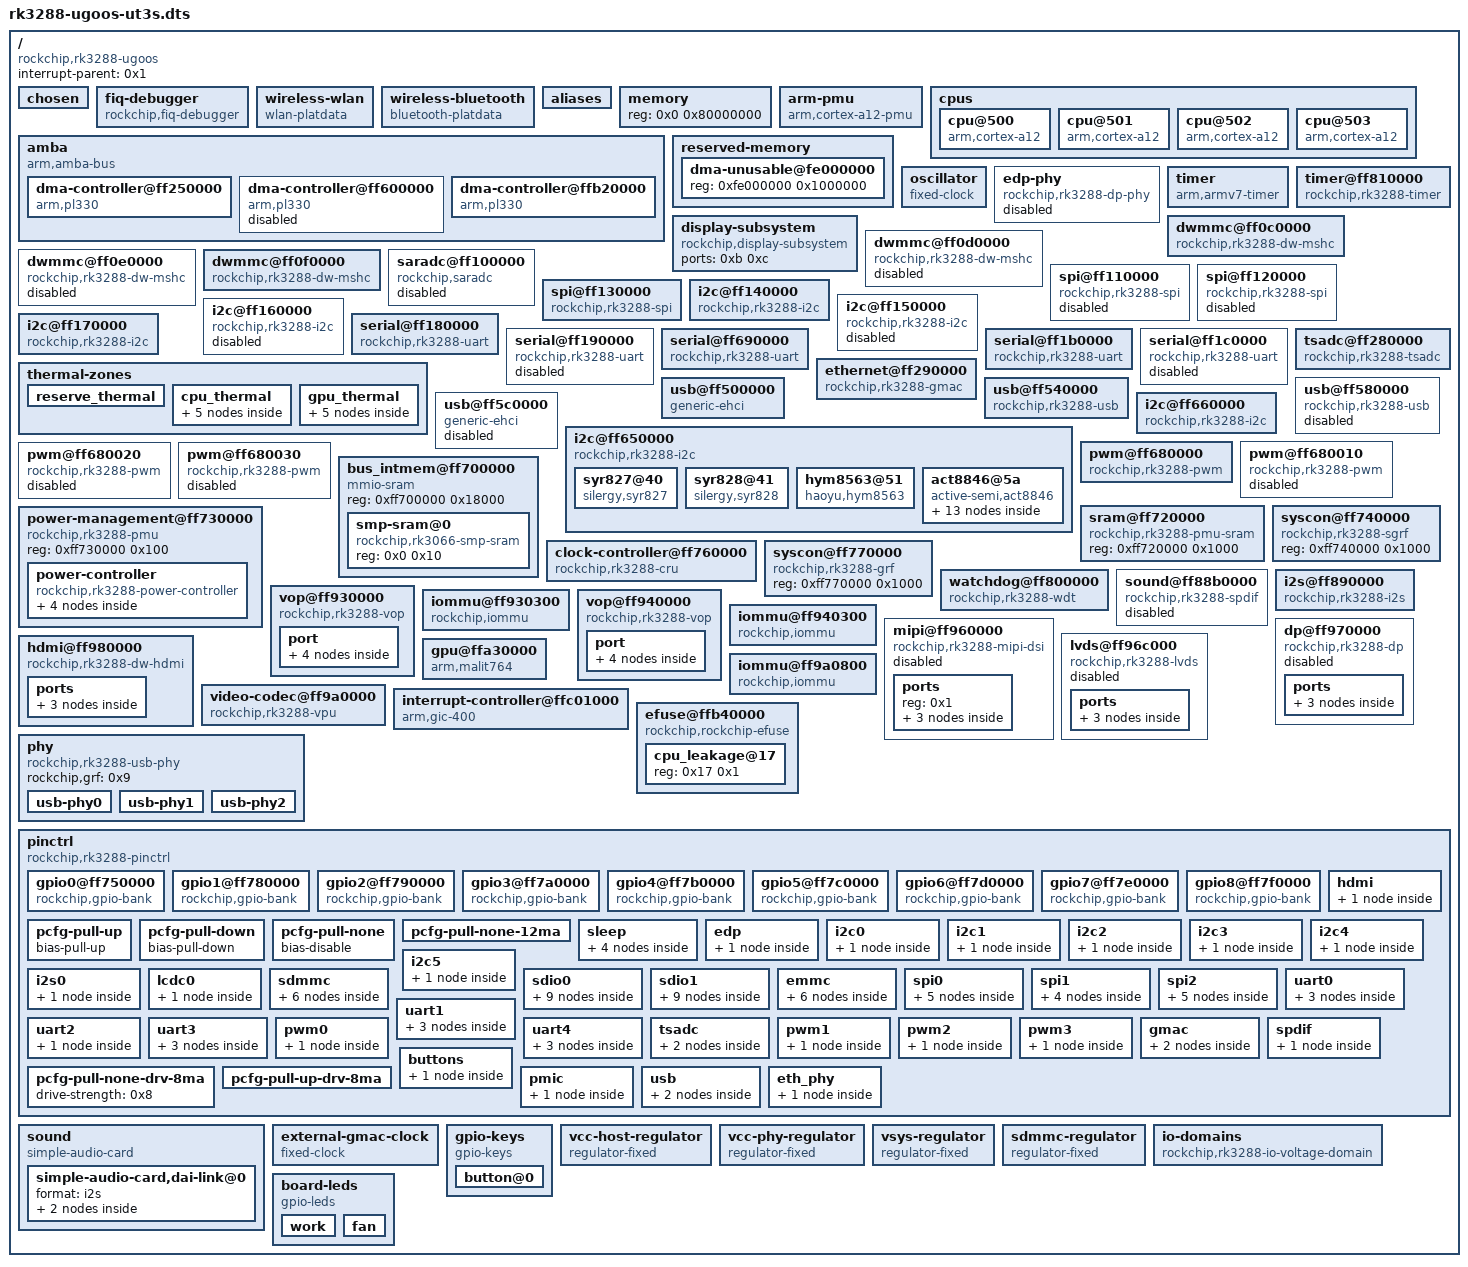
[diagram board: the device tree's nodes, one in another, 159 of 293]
/dts-v1/;

/ {
	#address-cells = <0x1>;
	#size-cells = <0x1>;
	compatible = "rockchip,rk3288-ugoos", "rockchip,rk3288";
	interrupt-parent = <0x1>;

	// Omegamoon >> Beware, 'bootargs' overrules hardcoded defconfig settings, and extends bootloader cmdline
	// 	for complete linux userspace logging: CONFIG_FIQ_DEBUGGER_CONSOLE_DEFAULT_ENABLE=y
	chosen {
		// Some options that might come in handy: 
		//   initcall_debug udev.log-priority=8 
		//   console=tty0 console=ttyS2,115200 
		//   root=/dev/mmcblk0p1 rootwait rootfstype=ext4 rw init=/sbin/init 
		//   mtdparts=rk29xxnand:0x00008000@0x00002000(boot),-@0x0000A000(linuxroot)
		//   mac_addr=de:ad:de:ad:be:ef
		// Insane debugging options (when nothing else works):
		//   ignore_loglevel debug debug_locks_verbose=1 sched_debug initcall_debug mminit_loglevel=4 udev.log_priority=8 loglevel=8 earlyprintk=vga,keep log_buf_len=10M print_fatal_signals=1 apm.debug=Y i8042.debug=Y drm.debug=1 scsi_logging_level=1 usbserial.debug=Y option.debug=Y pl2303.debug=Y firewire_ohci.debug=1 hid.debug=1 pci_hotplug.debug=Y pci_hotplug.debug_acpi=Y shpchp.shpchp_debug=Y apic=debug show_lapic=all hpet=verbose lmb=debug pause_on_oops=5 panic=10 sysrq_always_enabled
		//[buildscript_release]bootargs = "clk_ignore_unused debug earlyprintk keep_bootcon no_console_suspend verbose=1 pause_on_oops=20 panic=10 loglevel=8";
	};

	fiq-debugger {
		compatible = "rockchip,fiq-debugger";
		rockchip,serial-id = <0x2>;
		rockchip,signal-irq = <0x6a>;
		rockchip,wake-irq = <0x0>;
		status = "okay";
	};

	wireless-wlan {
		compatible = "wlan-platdata";

                /* wifi_chip_type - wifi chip define
                 * bcmwifi ==> like ap6xxx, rk90x;
                 * rtkwifi ==> like rtl8188xx, rtl8723xx,rtl8812auv;
                 * esp8089 ==> esp8089;
                 * other   ==> for other wifi;
                 */
		wifi_chip_type = "bcmwifi";
		sdio_vref = <1800>;               // 1800mv or 3300mv 

		power_pmu_regulator = "act_ldo3";
		power_pmu_enable_level = <1>;     // 1->HIGH, 0->LOW

		vref_pmu_regulator = "act_ldo3";
		vref_pmu_enable_level = <1>;      // 1->HIGH, 0->LOW
 
		WIFI,poweren_gpio = <0x5 0x1c 0x0>;
		WIFI,host_wake_irq = <0x5 0x1e 0x0>;

		status = "okay";
	};

	wireless-bluetooth {
		compatible = "bluetooth-platdata";
		uart_rts_gpios = <0x5 0x13 0x1>;
		pinctrl-names = "default", "rts_gpio";
		pinctrl-0 = <0x113>;
		pinctrl-1 = <0x114>;
		BT,power_gpio = <0x5 0x1b 0x0>;
		BT,reset_gpio = <0x5 0x1d 0x0>;
		BT,wake_gpio = <0x5 0x1a 0x0>;
		BT,wake_host_irq = <0x5 0x1f 0x0>;
		status = "okay";
	};

	aliases {
		i2c0 = "/i2c@ff650000";
		i2c1 = "/i2c@ff140000";
		i2c2 = "/i2c@ff660000";
		i2c3 = "/i2c@ff150000";
		i2c4 = "/i2c@ff160000";
		i2c5 = "/i2c@ff170000";
		mshc0 = "/dwmmc@ff0f0000";
		mshc1 = "/dwmmc@ff0c0000";
		mshc2 = "/dwmmc@ff0d0000";
		mshc3 = "/dwmmc@ff0e0000";
		serial0 = "/serial@ff180000";
		serial1 = "/serial@ff190000";
		serial2 = "/serial@ff690000";
		serial3 = "/serial@ff1b0000";
		serial4 = "/serial@ff1c0000";
		spi0 = "/spi@ff110000";
		spi1 = "/spi@ff120000";
		spi2 = "/spi@ff130000";
	};

	memory {
		device_type = "memory";
		reg = <0x0 0x80000000>;
	};

	arm-pmu {
		compatible = "arm,cortex-a12-pmu";
		interrupts = <0x0 0x97 0x4 0x0 0x98 0x4 0x0 0x99 0x4 0x0 0x9a 0x4>;
		interrupt-affinity = <0x2 0x3 0x4 0x5>;
	};

	cpus {
		#address-cells = <0x1>;
		#size-cells = <0x0>;
		enable-method = "rockchip,rk3066-smp";
		rockchip,pmu = <0x6>;

		cpu@500 {
			device_type = "cpu";
			compatible = "arm,cortex-a12";
			reg = <0x500>;
			resets = <0x7 0x0>;
			operating-points = <0x1b7740 0x155cc0 0x1a0040 0x149970 0x188940 0x13d620 0x171240 0x1312d0 0x159b40 0x124f80 0x124f80 0x10c8e0>;
			#cooling-cells = <0x2>;
			clock-latency = <0x9c40>;
			clocks = <0x7 0x6>;
			cpu0-supply = <0x8>;
			linux,phandle = <0x2>;
			phandle = <0x2>;
		};

		cpu@501 {
			device_type = "cpu";
			compatible = "arm,cortex-a12";
			reg = <0x501>;
			resets = <0x7 0x1>;
			linux,phandle = <0x3>;
			phandle = <0x3>;
		};

		cpu@502 {
			device_type = "cpu";
			compatible = "arm,cortex-a12";
			reg = <0x502>;
			resets = <0x7 0x2>;
			linux,phandle = <0x4>;
			phandle = <0x4>;
		};

		cpu@503 {
			device_type = "cpu";
			compatible = "arm,cortex-a12";
			reg = <0x503>;
			resets = <0x7 0x3>;
			linux,phandle = <0x5>;
			phandle = <0x5>;
		};
	};

	amba {
		compatible = "arm,amba-bus";
		#address-cells = <0x1>;
		#size-cells = <0x1>;
		ranges;

		dma-controller@ff250000 {
			compatible = "arm,pl330", "arm,primecell";
			reg = <0xff250000 0x4000>;
			interrupts = <0x0 0x2 0x4 0x0 0x3 0x4>;
			#dma-cells = <0x1>;
			arm,pl330-broken-no-flushp;
			peripherals-req-type-burst;
			clocks = <0x7 0xc2>;
			clock-names = "apb_pclk";
			linux,phandle = <0x17>;
			phandle = <0x17>;
		};

		dma-controller@ff600000 {
			compatible = "arm,pl330", "arm,primecell";
			reg = <0xff600000 0x4000>;
			interrupts = <0x0 0x0 0x4 0x0 0x1 0x4>;
			#dma-cells = <0x1>;
			arm,pl330-broken-no-flushp;
			peripherals-req-type-burst;
			clocks = <0x7 0xc1>;
			clock-names = "apb_pclk";
			status = "disabled";
		};

		dma-controller@ffb20000 {
			compatible = "arm,pl330", "arm,primecell";
			reg = <0xffb20000 0x4000>;
			interrupts = <0x0 0x0 0x4 0x0 0x1 0x4>;
			#dma-cells = <0x1>;
			arm,pl330-broken-no-flushp;
			peripherals-req-type-burst;
			clocks = <0x7 0xc1>;
			clock-names = "apb_pclk";
			linux,phandle = <0x44>;
			phandle = <0x44>;
		};
	};

	reserved-memory {
		#address-cells = <0x1>;
		#size-cells = <0x1>;
		ranges;

		dma-unusable@fe000000 {
			reg = <0xfe000000 0x1000000>;
		};
	};

	oscillator {
		compatible = "fixed-clock";
		clock-frequency = <0x16e3600>;
		clock-output-names = "xin24m";
		#clock-cells = <0x0>;
		linux,phandle = <0xa>;
		phandle = <0xa>;
	};

	edp-phy {
		compatible = "rockchip,rk3288-dp-phy";
		clocks = <0x7 0x68>;
		clock-names = "24m";
		rockchip,grf = <0x9>;
		#phy-cells = <0x0>;
		status = "disabled";
		linux,phandle = <0x54>;
		phandle = <0x54>;
	};

	timer {
		compatible = "arm,armv7-timer";
		arm,cpu-registers-not-fw-configured;
		interrupts = <0x1 0xd 0xf04 0x1 0xe 0xf04 0x1 0xb 0xf04 0x1 0xa 0xf04>;
		clock-frequency = <0x16e3600>;
	};

	timer@ff810000 {
		compatible = "rockchip,rk3288-timer";
		reg = <0xff810000 0x20>;
		interrupts = <0x0 0x48 0x4>;
		clocks = <0xa 0x7 0x161>;
		clock-names = "timer", "pclk";
	};

	display-subsystem {
		compatible = "rockchip,display-subsystem";
		ports = <0xb 0xc>;
	};

	dwmmc@ff0c0000 {
		compatible = "rockchip,rk3288-dw-mshc";
		clock-freq-min-max = <0x61a80 0x8f0d180>;
		clocks = <0x7 0x1c8 0x7 0x44 0x7 0x72 0x7 0x76>;
		clock-names = "biu", "ciu", "ciu-drive", "ciu-sample";
		fifo-depth = <0x100>;
		interrupts = <0x0 0x20 0x4>;
		reg = <0xff0c0000 0x4000>;
		status = "okay";
		supports-sd;
		bus-width = <0x4>;
		cap-mmc-highspeed;
		sd-uhs-sdr12;
		sd-uhs-sdr25;
		sd-uhs-sdr50;
		sd-uhs-sdr104;
		cap-sd-highspeed;
		card-detect-delay = <0xc8>;
		disable-wp;
		num-slots = <0x1>;
		pinctrl-names = "default";
		pinctrl-0 = <0xd 0xe 0xf 0x10>;
		vmmc-supply = <0x11>;
		vqmmc-supply = <0x12>;
	};

	dwmmc@ff0d0000 {
		compatible = "rockchip,rk3288-dw-mshc";
		clock-freq-min-max = <0x61a80 0x8f0d180>;
		clocks = <0x7 0x1c9 0x7 0x45 0x7 0x73 0x7 0x77>;
		clock-names = "biu", "ciu", "ciu-drive", "ciu-sample";
		fifo-depth = <0x100>;
		interrupts = <0x0 0x21 0x4>;
		reg = <0xff0d0000 0x4000>;
		status = "disabled";
	};

	dwmmc@ff0e0000 {
		compatible = "rockchip,rk3288-dw-mshc";
		clock-freq-min-max = <0x61a80 0x8f0d180>;
		clocks = <0x7 0x1ca 0x7 0x46 0x7 0x74 0x7 0x78>;
		clock-names = "biu", "ciu", "ciu-drive", "ciu-sample";
		fifo-depth = <0x100>;
		interrupts = <0x0 0x22 0x4>;
		reg = <0xff0e0000 0x4000>;
		status = "disabled";
	};

	dwmmc@ff0f0000 {
		compatible = "rockchip,rk3288-dw-mshc";
		clock-freq-min-max = <0x61a80 0x8f0d180>;
		clocks = <0x7 0x1cb 0x7 0x47 0x7 0x75 0x7 0x79>;
		clock-names = "biu", "ciu", "ciu-drive", "ciu-sample";
		fifo-depth = <0x100>;
		interrupts = <0x0 0x23 0x4>;
		reg = <0xff0f0000 0x4000>;
		status = "okay";
		supports-emmc;
		bus-width = <0x8>;
		cap-mmc-highspeed;
		disable-wp;
		non-removable;
		clock-frequency = <0x47868c0>;
		num-slots = <0x1>;
		pinctrl-names = "default";
		pinctrl-0 = <0x13 0x14 0x15 0x16>;
	};

	saradc@ff100000 {
		compatible = "rockchip,saradc";
		reg = <0xff100000 0x100>;
		interrupts = <0x0 0x24 0x4>;
		#io-channel-cells = <0x1>;
		clocks = <0x7 0x49 0x7 0x15b>;
		clock-names = "saradc", "apb_pclk";
		status = "disabled";
	};

	spi@ff110000 {
		compatible = "rockchip,rk3288-spi", "rockchip,rk3066-spi";
		clocks = <0x7 0x41 0x7 0x152>;
		clock-names = "spiclk", "apb_pclk";
		dmas = <0x17 0xb 0x17 0xc>;
		dma-names = "tx", "rx";
		interrupts = <0x0 0x2c 0x4>;
		pinctrl-names = "default";
		pinctrl-0 = <0x18 0x19 0x1a 0x1b>;
		reg = <0xff110000 0x1000>;
		#address-cells = <0x1>;
		#size-cells = <0x0>;
		status = "disabled";
	};

	spi@ff120000 {
		compatible = "rockchip,rk3288-spi", "rockchip,rk3066-spi";
		clocks = <0x7 0x42 0x7 0x153>;
		clock-names = "spiclk", "apb_pclk";
		dmas = <0x17 0xd 0x17 0xe>;
		dma-names = "tx", "rx";
		interrupts = <0x0 0x2d 0x4>;
		pinctrl-names = "default";
		pinctrl-0 = <0x1c 0x1d 0x1e 0x1f>;
		reg = <0xff120000 0x1000>;
		#address-cells = <0x1>;
		#size-cells = <0x0>;
		status = "disabled";
	};

	spi@ff130000 {
		compatible = "rockchip,rk3288-spi", "rockchip,rk3066-spi";
		clocks = <0x7 0x43 0x7 0x154>;
		clock-names = "spiclk", "apb_pclk";
		dmas = <0x17 0xf 0x17 0x10>;
		dma-names = "tx", "rx";
		interrupts = <0x0 0x2e 0x4>;
		pinctrl-names = "default";
		pinctrl-0 = <0x20 0x21 0x22 0x23>;
		reg = <0xff130000 0x1000>;
		#address-cells = <0x1>;
		#size-cells = <0x0>;
		status = "okay";
	};

	i2c@ff140000 {
		compatible = "rockchip,rk3288-i2c";
		reg = <0xff140000 0x1000>;
		interrupts = <0x0 0x3e 0x4>;
		#address-cells = <0x1>;
		#size-cells = <0x0>;
		clock-names = "i2c";
		clocks = <0x7 0x14d>;
		pinctrl-names = "default";
		pinctrl-0 = <0x24>;
		status = "okay";
	};

	i2c@ff150000 {
		compatible = "rockchip,rk3288-i2c";
		reg = <0xff150000 0x1000>;
		interrupts = <0x0 0x3f 0x4>;
		#address-cells = <0x1>;
		#size-cells = <0x0>;
		clock-names = "i2c";
		clocks = <0x7 0x14f>;
		pinctrl-names = "default";
		pinctrl-0 = <0x25>;
		status = "disabled";
	};

	i2c@ff160000 {
		compatible = "rockchip,rk3288-i2c";
		reg = <0xff160000 0x1000>;
		interrupts = <0x0 0x40 0x4>;
		#address-cells = <0x1>;
		#size-cells = <0x0>;
		clock-names = "i2c";
		clocks = <0x7 0x150>;
		pinctrl-names = "default";
		pinctrl-0 = <0x26>;
		status = "disabled";
	};

	i2c@ff170000 {
		compatible = "rockchip,rk3288-i2c";
		reg = <0xff170000 0x1000>;
		interrupts = <0x0 0x41 0x4>;
		#address-cells = <0x1>;
		#size-cells = <0x0>;
		clock-names = "i2c";
		clocks = <0x7 0x151>;
		pinctrl-names = "default";
		pinctrl-0 = <0x27>;
		status = "okay";
		linux,phandle = <0x5a>;
		phandle = <0x5a>;
	};

	serial@ff180000 {
/*
// Omegamoon >> Ugoos UT3S 3.10 kernel
		compatible = "rockchip,serial";
		reg = <0xff180000 0x100>;
		interrupts = <0x0 0x37 0x4>;
		clock-frequency = <0x16e3600>;
		clocks = <0x9f 0x7b 0x8>;
		clock-names = "sclk_uart", "pclk_uart";
		reg-shift = <0x2>;
		reg-io-width = <0x4>;
		dmas = <0x93 0x1 0x93 0x2>;
		#dma-cells = <0x2>;
		pinctrl-names = "default";
		pinctrl-0 = <0xa0 0xa1>;
		status = "okay";
		dma-names = "!tx", "!rx";
// Omegamoon >> rockchip rk3288 default
		compatible = "rockchip,rk3288-uart", "snps,dw-apb-uart";
		reg = <0xff180000 0x100>;
		interrupts = <0x0 0x37 0x4>;
		reg-shift = <0x2>;
		reg-io-width = <0x4>;
		clocks = <0x7 0x4d 0x7 0x155>;
		clock-names = "baudclk", "apb_pclk";
		pinctrl-names = "default";
		pinctrl-0 = <0x28>;
		status = "disabled";
*/
		compatible = "rockchip,rk3288-uart", "snps,dw-apb-uart";
		reg = <0xff180000 0x100>;
		interrupts = <0x0 0x37 0x4>;
		reg-shift = <0x2>;
		reg-io-width = <0x4>;
		clocks = <0x7 0x4d 0x7 0x155>;
		clock-names = "baudclk", "apb_pclk";

		dmas = <0x93 0x1 0x93 0x2>;
		#dma-cells = <0x2>;
		pinctrl-names = "default";
		pinctrl-0 = <0xa0 0xa1>;
		status = "okay";
		dma-names = "!tx", "!rx";
	};

	serial@ff190000 {
		compatible = "rockchip,rk3288-uart", "snps,dw-apb-uart";
		reg = <0xff190000 0x100>;
		interrupts = <0x0 0x38 0x4>;
		reg-shift = <0x2>;
		reg-io-width = <0x4>;
		clocks = <0x7 0x4e 0x7 0x156>;
		clock-names = "baudclk", "apb_pclk";
		pinctrl-names = "default";
		pinctrl-0 = <0x29>;
		status = "disabled";
	};

	serial@ff690000 {
		compatible = "rockchip,rk3288-uart", "snps,dw-apb-uart";
		reg = <0xff690000 0x100>;
		interrupts = <0x0 0x39 0x4>;
		reg-shift = <0x2>;
		reg-io-width = <0x4>;
		clocks = <0x7 0x4f 0x7 0x157>;
		clock-names = "baudclk", "apb_pclk";
		pinctrl-names = "default";
		pinctrl-0 = <0x2a>;
		status = "okay";
	};

	serial@ff1b0000 {
		compatible = "rockchip,rk3288-uart", "snps,dw-apb-uart";
		reg = <0xff1b0000 0x100>;
		interrupts = <0x0 0x3a 0x4>;
		reg-shift = <0x2>;
		reg-io-width = <0x4>;
		clocks = <0x7 0x50 0x7 0x158>;
		clock-names = "baudclk", "apb_pclk";
		pinctrl-names = "default";
		pinctrl-0 = <0x2b>;
		status = "okay";
	};

	serial@ff1c0000 {
		compatible = "rockchip,rk3288-uart", "snps,dw-apb-uart";
		reg = <0xff1c0000 0x100>;
		interrupts = <0x0 0x3b 0x4>;
		reg-shift = <0x2>;
		reg-io-width = <0x4>;
		clocks = <0x7 0x51 0x7 0x159>;
		clock-names = "baudclk", "apb_pclk";
		pinctrl-names = "default";
		pinctrl-0 = <0x2c>;
		status = "disabled";
	};

	thermal-zones {

		reserve_thermal {
			polling-delay-passive = <0x3e8>;
			polling-delay = <0x1388>;
			thermal-sensors = <0x2d 0x0>;
		};

		cpu_thermal {
			polling-delay-passive = <0x3e8>;
			polling-delay = <0x1388>;
			thermal-sensors = <0x2d 0x1>;

			trips {

				cpu_alert0 {
					temperature = <0x11170>;
					hysteresis = <0x7d0>;
					type = "passive";
					linux,phandle = <0x2e>;
					phandle = <0x2e>;
				};

				cpu_crit {
					temperature = <0x15f90>;
					hysteresis = <0x7d0>;
					type = "critical";
				};
			};

			cooling-maps {

				map0 {
					trip = <0x2e>;
					cooling-device = <0x2 0xffffffff 0xffffffff>;
				};
			};
		};

		gpu_thermal {
			polling-delay-passive = <0x3e8>;
			polling-delay = <0x1388>;
			thermal-sensors = <0x2d 0x2>;

			trips {

				gpu_alert0 {
					temperature = <0x11170>;
					hysteresis = <0x7d0>;
					type = "passive";
					linux,phandle = <0x2f>;
					phandle = <0x2f>;
				};

				gpu_crit {
					temperature = <0x15f90>;
					hysteresis = <0x7d0>;
					type = "critical";
				};
			};

			cooling-maps {

				map0 {
					trip = <0x2f>;
					cooling-device = <0x2 0xffffffff 0xffffffff>;
				};
			};
		};
	};

	tsadc@ff280000 {
		compatible = "rockchip,rk3288-tsadc";
		reg = <0xff280000 0x100>;
		interrupts = <0x0 0x25 0x4>;
		clocks = <0x7 0x48 0x7 0x15a>;
		clock-names = "tsadc", "apb_pclk";
		resets = <0x7 0x9f>;
		reset-names = "tsadc-apb";
		pinctrl-names = "init", "default", "sleep";
		pinctrl-0 = <0x30>;
		pinctrl-1 = <0x31>;
		pinctrl-2 = <0x30>;
		#thermal-sensor-cells = <0x1>;
		rockchip,hw-tshut-temp = <0x17318>;
		status = "okay";
		rockchip,hw-tshut-mode = <0x1>;
		rockchip,hw-tshut-polarity = <0x1>;
		linux,phandle = <0x2d>;
		phandle = <0x2d>;
	};

	ethernet@ff290000 {
		compatible = "rockchip,rk3288-gmac";
		reg = <0xff290000 0x10000>;
		interrupts = <0x0 0x1b 0x4>;
		interrupt-names = "macirq";
		rockchip,grf = <0x9>;
		clocks = <0x7 0x97 0x7 0x66 0x7 0x67 0x7 0x63 0x7 0x98 0x7 0xc4 0x7 0x15d>;
		clock-names = "stmmaceth", "mac_clk_rx", "mac_clk_tx", "clk_mac_ref", "clk_mac_refout", "aclk_mac", "pclk_mac";
		resets = <0x7 0x42>;
		reset-names = "stmmaceth";
		status = "ok";
		phy-supply = <0x32>;
		phy-mode = "rgmii";
		clock_in_out = "input";
		snps,reset-gpio = <0x33 0x7 0x0>;
		snps,reset-active-low;
		snps,reset-delays-us = <0x0 0x2710 0xf4240>;
		assigned-clocks = <0x7 0x97>;
		assigned-clock-parents = <0x34>;
		pinctrl-names = "default";
		pinctrl-0 = <0x35>;
		tx_delay = <0x30>;
		rx_delay = <0x10>;
	};

	usb@ff500000 {
		compatible = "generic-ehci";
		reg = <0xff500000 0x100>;
		interrupts = <0x0 0x18 0x4>;
		clocks = <0x7 0x1c2>;
		clock-names = "usbhost";
		phys = <0x36>;
		phy-names = "usb";
		status = "okay";
	};

	usb@ff540000 {
		compatible = "rockchip,rk3288-usb", "rockchip,rk3066-usb", "snps,dwc2";
		reg = <0xff540000 0x40000>;
		interrupts = <0x0 0x19 0x4>;
		clocks = <0x7 0x1c3>;
		clock-names = "otg";
		dr_mode = "host";
		phys = <0x37>;
		phy-names = "usb2-phy";
		status = "okay";
	};

	usb@ff580000 {
		compatible = "rockchip,rk3288-usb", "rockchip,rk3066-usb", "snps,dwc2";
		reg = <0xff580000 0x40000>;
		interrupts = <0x0 0x17 0x4>;
		clocks = <0x7 0x1c1>;
		clock-names = "otg";
		dr_mode = "otg";
		g-np-tx-fifo-size = <0x10>;
		g-rx-fifo-size = <0x113>;
		g-tx-fifo-size = <0x100 0x80 0x80 0x40 0x40 0x20>;
		g-use-dma;
		phys = <0x38>;
		phy-names = "usb2-phy";
		status = "disabled";
	};

	usb@ff5c0000 {
		compatible = "generic-ehci";
		reg = <0xff5c0000 0x100>;
		interrupts = <0x0 0x1a 0x4>;
		clocks = <0x7 0x1c4>;
		clock-names = "usbhost";
		status = "disabled";
	};

	i2c@ff650000 {
		compatible = "rockchip,rk3288-i2c";
		reg = <0xff650000 0x1000>;
		interrupts = <0x0 0x3c 0x4>;
		#address-cells = <0x1>;
		#size-cells = <0x0>;
		clock-names = "i2c";
		clocks = <0x7 0x14c>;
		pinctrl-names = "default";
		pinctrl-0 = <0x39>;
		status = "okay";
		clock-frequency = <0x61a80>;

		syr827@40 {
			compatible = "silergy,syr827";
			fcs,suspend-voltage-selector = <0x1>;
			reg = <0x40>;
			regulator-name = "vdd_cpu";
			regulator-min-microvolt = <0xadf34>;
			regulator-max-microvolt = <0x16e360>;
			regulator-always-on;
			regulator-boot-on;
			regulator-enable-ramp-delay = <0x12c>;
			regulator-ramp-delay = <0x1f40>;
			vin-supply = <0x3a>;
			linux,phandle = <0x8>;
			phandle = <0x8>;
		};

		syr828@41 {
			compatible = "silergy,syr828";
			fcs,suspend-voltage-selector = <0x1>;
			reg = <0x41>;
			regulator-name = "vdd_gpu";
			regulator-min-microvolt = <0xadf34>;
			regulator-max-microvolt = <0x16e360>;
			regulator-always-on;
			vin-supply = <0x3a>;
			linux,phandle = <0x5d>;
			phandle = <0x5d>;
		};

		hym8563@51 {
			compatible = "haoyu,hym8563";
			reg = <0x51>;
			interrupt-parent = <0x3b>;
			interrupts = <0x4 0x2>;
			pinctrl-names = "default";
			pinctrl-0 = <0x3c>;
			#clock-cells = <0x0>;
			clock-output-names = "xin32k";
		};

		act8846@5a {
			compatible = "active-semi,act8846";
			reg = <0x5a>;
			status = "okay";
			system-power-controller;
			vp1-supply = <0x3a>;
			vp2-supply = <0x3a>;
			vp3-supply = <0x3a>;
			vp4-supply = <0x3a>;
			inl1-supply = <0x3d>;
			inl2-supply = <0x3a>;
			inl3-supply = <0x3e>;

			regulators {

				REG1 {
					regulator-name = "VCC_DDR";
					regulator-min-microvolt = <0x124f80>;
					regulator-max-microvolt = <0x124f80>;
					regulator-always-on;
				};

				REG2 {
					regulator-name = "VCC_IO";
					regulator-min-microvolt = <0x325aa0>;
					regulator-max-microvolt = <0x325aa0>;
					regulator-always-on;
					linux,phandle = <0x3d>;
					phandle = <0x3d>;
				};

				REG3 {
					regulator-name = "VDD_LOG";
					regulator-min-microvolt = <0xf4240>;
					regulator-max-microvolt = <0xf4240>;
					regulator-always-on;
				};

				REG4 {
					regulator-name = "VCC_20";
					regulator-min-microvolt = <0x1e8480>;
					regulator-max-microvolt = <0x1e8480>;
					regulator-always-on;
					linux,phandle = <0x3e>;
					phandle = <0x3e>;
				};

				REG5 {
					regulator-name = "VCCIO_SD";
					regulator-min-microvolt = <0x1b7740>;
					regulator-max-microvolt = <0x325aa0>;
					regulator-always-on;
					linux,phandle = <0x12>;
					phandle = <0x12>;
				};

				REG6 {
					regulator-name = "VDD10_LCD";
					regulator-min-microvolt = <0xf4240>;
					regulator-max-microvolt = <0xf4240>;
					regulator-always-on;
				};

				REG7 {
					regulator-name = "VCCA_CODEC";
					regulator-min-microvolt = <0x325aa0>;
					regulator-max-microvolt = <0x325aa0>;
					regulator-always-on;
				};

				REG8 {
					regulator-name = "VCCA_TP";
					regulator-min-microvolt = <0x325aa0>;
					regulator-max-microvolt = <0x325aa0>;
					regulator-always-on;
				};

				REG9 {
					regulator-name = "VCCIO_PMU";
					regulator-min-microvolt = <0x325aa0>;
					regulator-max-microvolt = <0x325aa0>;
					regulator-always-on;
				};

				REG10 {
					regulator-name = "VDD_10";
					regulator-min-microvolt = <0xf4240>;
					regulator-max-microvolt = <0xf4240>;
					regulator-always-on;
				};

				REG11 {
					regulator-name = "VCC_18";
					regulator-min-microvolt = <0x1b7740>;
					regulator-max-microvolt = <0x1b7740>;
					regulator-always-on;
				};

				REG12 {
					regulator-name = "VCC18_LCD";
					regulator-min-microvolt = <0x1b7740>;
					regulator-max-microvolt = <0x1b7740>;
					regulator-always-on;
				};
			};
		};
	};

	i2c@ff660000 {
		compatible = "rockchip,rk3288-i2c";
		reg = <0xff660000 0x1000>;
		interrupts = <0x0 0x3d 0x4>;
		#address-cells = <0x1>;
		#size-cells = <0x0>;
		clock-names = "i2c";
		clocks = <0x7 0x14e>;
		pinctrl-names = "default";
		pinctrl-0 = <0x3f>;
		status = "okay";
	};

	pwm@ff680000 {
		compatible = "rockchip,rk3288-pwm";
		reg = <0xff680000 0x10>;
		#pwm-cells = <0x3>;
		pinctrl-names = "default";
		pinctrl-0 = <0x40>;
		clocks = <0x7 0x15e>;
		clock-names = "pwm";
		status = "okay";
	};

	pwm@ff680010 {
		compatible = "rockchip,rk3288-pwm";
		reg = <0xff680010 0x10>;
		#pwm-cells = <0x3>;
		pinctrl-names = "default";
		pinctrl-0 = <0x41>;
		clocks = <0x7 0x15e>;
		clock-names = "pwm";
		status = "disabled";
	};

	pwm@ff680020 {
		compatible = "rockchip,rk3288-pwm";
		reg = <0xff680020 0x10>;
		#pwm-cells = <0x3>;
		pinctrl-names = "default";
		pinctrl-0 = <0x42>;
		clocks = <0x7 0x15e>;
		clock-names = "pwm";
		status = "disabled";
	};

	pwm@ff680030 {
		compatible = "rockchip,rk3288-pwm";
		reg = <0xff680030 0x10>;
		#pwm-cells = <0x2>;
		pinctrl-names = "default";
		pinctrl-0 = <0x43>;
		clocks = <0x7 0x15e>;
		clock-names = "pwm";
		status = "disabled";
	};

	bus_intmem@ff700000 {
		compatible = "mmio-sram";
		reg = <0xff700000 0x18000>;
		#address-cells = <0x1>;
		#size-cells = <0x1>;
		ranges = <0x0 0xff700000 0x18000>;

		smp-sram@0 {
			compatible = "rockchip,rk3066-smp-sram";
			reg = <0x0 0x10>;
		};
	};

	sram@ff720000 {
		compatible = "rockchip,rk3288-pmu-sram", "mmio-sram";
		reg = <0xff720000 0x1000>;
	};

	power-management@ff730000 {
		compatible = "rockchip,rk3288-pmu", "syscon", "simple-mfd";
		reg = <0xff730000 0x100>;
		linux,phandle = <0x6>;
		phandle = <0x6>;

		power-controller {
			compatible = "rockchip,rk3288-power-controller";
			#power-domain-cells = <0x1>;
			#address-cells = <0x1>;
			#size-cells = <0x0>;
			linux,phandle = <0x47>;
			phandle = <0x47>;

			pd_vio {
				reg = <0x9>;
				clocks = <0x7 0xca 0x7 0xcd 0x7 0xc8 0x7 0xcc 0x7 0xc5 0x7 0xc6 0x7 0xbe 0x7 0xbf 0x7 0x1d4 0x7 0x1d5 0x7 0x1d6 0x7 0x1d9 0x7 0x1d1 0x7 0x1d2 0x7 0x163 0x7 0x168 0x7 0x167 0x7 0x166 0x7 0x164 0x7 0x165 0x7 0x68 0x7 0x69 0x7 0x6c 0x7 0x6b 0x7 0x6a>;
			};

			pd_hevc {
				reg = <0xb>;
				clocks = <0x7 0xcf 0x7 0x6f 0x7 0x70>;
			};

			pd_video {
				reg = <0xc>;
				clocks = <0x7 0xd0 0x7 0x1dc>;
			};

			pd_gpu {
				reg = <0xd>;
				clocks = <0x7 0xc0>;
			};
		};
	};

	syscon@ff740000 {
		compatible = "rockchip,rk3288-sgrf", "syscon";
		reg = <0xff740000 0x1000>;
	};

	clock-controller@ff760000 {
		compatible = "rockchip,rk3288-cru";
		reg = <0xff760000 0x1000>;
		rockchip,grf = <0x9>;
		#clock-cells = <0x1>;
		#reset-cells = <0x1>;
		assigned-clocks = <0x7 0xbe 0x7 0xbf 0x7 0x4 0x7 0x3 0x7 0x5 0x7 0xd1 0x7 0x1dd 0x7 0x16a 0x7 0xd2 0x7 0x1de 0x7 0x16b>;
		assigned-clock-rates = <0x0 0x0 0x2367b880 0x17d78400 0x1dcd6500 0x11e1a300 0x8f0d180 0x47868c0 0x11e1a300 0x8f0d180 0x47868c0>;
		assigned-clock-parents = <0x7 0x5 0x7 0x4>;
		linux,phandle = <0x7>;
		phandle = <0x7>;
	};

	syscon@ff770000 {
		compatible = "rockchip,rk3288-grf", "syscon";
		reg = <0xff770000 0x1000>;
		linux,phandle = <0x9>;
		phandle = <0x9>;
	};

	watchdog@ff800000 {
		compatible = "rockchip,rk3288-wdt", "snps,dw-wdt";
		reg = <0xff800000 0x100>;
		clocks = <0x7 0x170>;
		interrupts = <0x0 0x4f 0x4>;
		status = "okay";
	};

	sound@ff88b0000 {
		compatible = "rockchip,rk3288-spdif", "rockchip,rk3066-spdif";
		reg = <0xff8b0000 0x10000>;
		#sound-dai-cells = <0x0>;
		clock-names = "hclk", "mclk";
		clocks = <0x7 0x1d0 0x7 0x54>;
		dmas = <0x44 0x3>;
		dma-names = "tx";
		interrupts = <0x0 0x55 0x4>;
		pinctrl-names = "default";
		pinctrl-0 = <0x45>;
		rockchip,grf = <0x9>;
		status = "disabled";
	};

	i2s@ff890000 {
		compatible = "rockchip,rk3288-i2s", "rockchip,rk3066-i2s";
		reg = <0xff890000 0x10000>;
		interrupts = <0x0 0x55 0x4>;
		#address-cells = <0x1>;
		#size-cells = <0x0>;
		dmas = <0x44 0x0 0x44 0x1>;
		dma-names = "tx", "rx";
		clock-names = "i2s_hclk", "i2s_clk";
		clocks = <0x7 0x1ce 0x7 0x52>;
		pinctrl-names = "default";
		pinctrl-0 = <0x46>;
		status = "okay";
		#sound-dai-cells = <0x0>;
		linux,phandle = <0x65>;
		phandle = <0x65>;
	};

	vop@ff930000 {
		compatible = "rockchip,rk3288-vop";
		reg = <0xff930000 0x19c>;
		interrupts = <0x0 0xf 0x4>;
		clocks = <0x7 0xc5 0x7 0xbe 0x7 0x1d1>;
		clock-names = "aclk_vop", "dclk_vop", "hclk_vop";
		power-domains = <0x47 0x9>;
		resets = <0x7 0x64 0x7 0x65 0x7 0x66>;
		reset-names = "axi", "ahb", "dclk";
		iommus = <0x48>;
		status = "okay";

		port {
			#address-cells = <0x1>;
			#size-cells = <0x0>;
			linux,phandle = <0xc>;
			phandle = <0xc>;

			endpoint@0 {
				reg = <0x0>;
				remote-endpoint = <0x49>;
				linux,phandle = <0x5b>;
				phandle = <0x5b>;
			};

			endpoint@1 {
				reg = <0x1>;
				remote-endpoint = <0x4a>;
				linux,phandle = <0x55>;
				phandle = <0x55>;
			};

			endpoint@2 {
				reg = <0x2>;
				remote-endpoint = <0x4b>;
				linux,phandle = <0x52>;
				phandle = <0x52>;
			};

			endpoint@3 {
				reg = <0x3>;
				remote-endpoint = <0x4c>;
				linux,phandle = <0x58>;
				phandle = <0x58>;
			};
		};
	};

	iommu@ff930300 {
		compatible = "rockchip,iommu";
		reg = <0xff930300 0x100>;
		interrupts = <0x0 0xf 0x4>;
		interrupt-names = "vopb_mmu";
		power-domains = <0x47 0x9>;
		#iommu-cells = <0x0>;
		status = "okay";
		linux,phandle = <0x48>;
		phandle = <0x48>;
	};

	vop@ff940000 {
		compatible = "rockchip,rk3288-vop";
		reg = <0xff940000 0x19c>;
		interrupts = <0x0 0x10 0x4>;
		clocks = <0x7 0xc6 0x7 0xbf 0x7 0x1d2>;
		clock-names = "aclk_vop", "dclk_vop", "hclk_vop";
		power-domains = <0x47 0x9>;
		resets = <0x7 0xb0 0x7 0xb1 0x7 0xb2>;
		reset-names = "axi", "ahb", "dclk";
		iommus = <0x4d>;
		status = "okay";

		port {
			#address-cells = <0x1>;
			#size-cells = <0x0>;
			linux,phandle = <0xb>;
			phandle = <0xb>;

			endpoint@0 {
				reg = <0x0>;
				remote-endpoint = <0x4e>;
				linux,phandle = <0x5c>;
				phandle = <0x5c>;
			};

			endpoint@1 {
				reg = <0x1>;
				remote-endpoint = <0x4f>;
				linux,phandle = <0x56>;
				phandle = <0x56>;
			};

			endpoint@2 {
				reg = <0x2>;
				remote-endpoint = <0x50>;
				linux,phandle = <0x53>;
				phandle = <0x53>;
			};

			endpoint@3 {
				reg = <0x3>;
				remote-endpoint = <0x51>;
				linux,phandle = <0x59>;
				phandle = <0x59>;
			};
		};
	};

	iommu@ff940300 {
		compatible = "rockchip,iommu";
		reg = <0xff940300 0x100>;
		interrupts = <0x0 0x10 0x4>;
		interrupt-names = "vopl_mmu";
		power-domains = <0x47 0x9>;
		#iommu-cells = <0x0>;
		status = "okay";
		linux,phandle = <0x4d>;
		phandle = <0x4d>;
	};

	mipi@ff960000 {
		compatible = "rockchip,rk3288-mipi-dsi", "snps,dw-mipi-dsi";
		reg = <0xff960000 0x4000>;
		interrupts = <0x0 0x53 0x4>;
		clocks = <0x7 0x7e 0x7 0x164>;
		clock-names = "ref", "pclk";
		rockchip,grf = <0x9>;
		#address-cells = <0x1>;
		#size-cells = <0x0>;
		status = "disabled";

		ports {
			#address-cells = <0x1>;
			#size-cells = <0x0>;
			reg = <0x1>;

			port {
				#address-cells = <0x1>;
				#size-cells = <0x0>;

				endpoint@0 {
					reg = <0x0>;
					remote-endpoint = <0x52>;
					linux,phandle = <0x4b>;
					phandle = <0x4b>;
				};

				endpoint@1 {
					reg = <0x1>;
					remote-endpoint = <0x53>;
					linux,phandle = <0x50>;
					phandle = <0x50>;
				};
			};
		};
	};

	dp@ff970000 {
		compatible = "rockchip,rk3288-dp";
		reg = <0xff970000 0x4000>;
		interrupts = <0x0 0x62 0x4>;
		clocks = <0x7 0x69 0x7 0x163>;
		clock-names = "dp", "pclk";
		phys = <0x54>;
		phy-names = "dp";
		resets = <0x7 0x6f>;
		reset-names = "dp";
		rockchip,grf = <0x9>;
		status = "disabled";

		ports {
			#address-cells = <0x1>;
			#size-cells = <0x0>;

			port@0 {
				reg = <0x0>;
				#address-cells = <0x1>;
				#size-cells = <0x0>;

				endpoint@0 {
					reg = <0x0>;
					remote-endpoint = <0x55>;
					linux,phandle = <0x4a>;
					phandle = <0x4a>;
				};

				endpoint@1 {
					reg = <0x1>;
					remote-endpoint = <0x56>;
					linux,phandle = <0x4f>;
					phandle = <0x4f>;
				};
			};
		};
	};

	lvds@ff96c000 {
		compatible = "rockchip,rk3288-lvds";
		reg = <0xff96c000 0x4000>;
		clocks = <0x7 0x167>;
		clock-names = "pclk_lvds";
		pinctrl-names = "default";
		pinctrl-0 = <0x57>;
		power-domains = <0x47 0x9>;
		rockchip,grf = <0x9>;
		status = "disabled";

		ports {
			#address-cells = <0x1>;
			#size-cells = <0x0>;

			port@0 {
				reg = <0x0>;
				#address-cells = <0x1>;
				#size-cells = <0x0>;

				endpoint@0 {
					reg = <0x0>;
					remote-endpoint = <0x58>;
					linux,phandle = <0x4c>;
					phandle = <0x4c>;
				};

				endpoint@1 {
					reg = <0x1>;
					remote-endpoint = <0x59>;
					linux,phandle = <0x51>;
					phandle = <0x51>;
				};
			};
		};
	};

	hdmi@ff980000 {
		compatible = "rockchip,rk3288-dw-hdmi";
		reg = <0xff980000 0x20000>;
		reg-io-width = <0x4>;
		rockchip,grf = <0x9>;
		interrupts = <0x0 0x67 0x4>;
		clocks = <0x7 0x168 0x7 0x6d>;
		clock-names = "iahb", "isfr";
		power-domains = <0x47 0x9>;
		status = "okay";
		#address-cells = <0x1>;
		#size-cells = <0x0>;
		#sound-dai-cells = <0x0>;
		ddc-i2c-bus = <0x5a>;
		linux,phandle = <0x66>;
		phandle = <0x66>;

		ports {

			port {
				#address-cells = <0x1>;
				#size-cells = <0x0>;

				endpoint@0 {
					reg = <0x0>;
					remote-endpoint = <0x5b>;
					linux,phandle = <0x49>;
					phandle = <0x49>;
				};

				endpoint@1 {
					reg = <0x1>;
					remote-endpoint = <0x5c>;
					linux,phandle = <0x4e>;
					phandle = <0x4e>;
				};
			};
		};
	};

	gpu@ffa30000 {
		compatible = "arm,malit764", "arm,malit76x", "arm,malit7xx", "arm,mali-midgard";
		reg = <0xffa30000 0x10000>;
		interrupts = <0x0 0x6 0x4 0x0 0x7 0x4 0x0 0x8 0x4>;
		interrupt-names = "JOB", "MMU", "GPU";
		clocks = <0x7 0xc0>;
		clock-names = "clk_mali";
		operating-points = <0x927c0 0x1312d0 0x61a80 0x10c8e0 0x493e0 0xf4240 0x30d40 0xe7ef0 0x186a0 0xe7ef0>;
		#cooling-cells = <0x2>;
		power-domains = <0x47 0xd>;
		status = "okay";
		mali-supply = <0x5d>;
		power-off-delay-ms = <0xc8>;
	};

	video-codec@ff9a0000 {
		compatible = "rockchip,rk3288-vpu";
		reg = <0xff9a0000 0x800>;
		interrupts = <0x0 0x9 0x4 0x0 0xa 0x4>;
		interrupt-names = "vepu", "vdpu";
		clocks = <0x7 0xd0 0x7 0x1dc>;
		clock-names = "aclk", "hclk";
		power-domains = <0x47 0xc>;
		iommus = <0x5e>;
		assigned-clocks = <0x7 0xd0>;
		assigned-clock-rates = <0x17d78400>;
		status = "okay";
	};

	iommu@ff9a0800 {
		compatible = "rockchip,iommu";
		reg = <0xff9a0800 0x100>;
		interrupts = <0x0 0xb 0x4>;
		interrupt-names = "vpu_mmu";
		power-domains = <0x47 0xc>;
		#iommu-cells = <0x0>;
		linux,phandle = <0x5e>;
		phandle = <0x5e>;
	};

	interrupt-controller@ffc01000 {
		compatible = "arm,gic-400";
		interrupt-controller;
		#interrupt-cells = <0x3>;
		#address-cells = <0x0>;
		reg = <0xffc01000 0x1000 0xffc02000 0x1000 0xffc04000 0x2000 0xffc06000 0x2000>;
		interrupts = <0x1 0x9 0xf04>;
		linux,phandle = <0x1>;
		phandle = <0x1>;
	};

	efuse@ffb40000 {
		compatible = "rockchip,rockchip-efuse";
		reg = <0xffb40000 0x20>;
		#address-cells = <0x1>;
		#size-cells = <0x1>;
		clocks = <0x7 0x171>;
		clock-names = "pclk_efuse";

		cpu_leakage@17 {
			reg = <0x17 0x1>;
		};
	};

	phy {
		compatible = "rockchip,rk3288-usb-phy";
		rockchip,grf = <0x9>;
		#address-cells = <0x1>;
		#size-cells = <0x0>;
		status = "okay";

		usb-phy0 {
			#phy-cells = <0x0>;
			reg = <0x320>;
			clocks = <0x7 0x5d>;
			clock-names = "phyclk";
			linux,phandle = <0x38>;
			phandle = <0x38>;
		};

		usb-phy1 {
			#phy-cells = <0x0>;
			reg = <0x334>;
			clocks = <0x7 0x5e>;
			clock-names = "phyclk";
			linux,phandle = <0x36>;
			phandle = <0x36>;
		};

		usb-phy2 {
			#phy-cells = <0x0>;
			reg = <0x348>;
			clocks = <0x7 0x5f>;
			clock-names = "phyclk";
			linux,phandle = <0x37>;
			phandle = <0x37>;
		};
	};

	pinctrl {
		compatible = "rockchip,rk3288-pinctrl";
		rockchip,grf = <0x9>;
		rockchip,pmu = <0x6>;
		#address-cells = <0x1>;
		#size-cells = <0x1>;
		ranges;

		gpio0@ff750000 {
			compatible = "rockchip,gpio-bank";
			reg = <0xff750000 0x100>;
			interrupts = <0x0 0x51 0x4>;
			clocks = <0x7 0x140>;
			gpio-controller;
			#gpio-cells = <0x2>;
			interrupt-controller;
			#interrupt-cells = <0x2>;
			linux,phandle = <0x3b>;
			phandle = <0x3b>;
		};

		gpio1@ff780000 {
			compatible = "rockchip,gpio-bank";
			reg = <0xff780000 0x100>;
			interrupts = <0x0 0x52 0x4>;
			clocks = <0x7 0x141>;
			gpio-controller;
			#gpio-cells = <0x2>;
			interrupt-controller;
			#interrupt-cells = <0x2>;
		};

		gpio2@ff790000 {
			compatible = "rockchip,gpio-bank";
			reg = <0xff790000 0x100>;
			interrupts = <0x0 0x53 0x4>;
			clocks = <0x7 0x142>;
			gpio-controller;
			#gpio-cells = <0x2>;
			interrupt-controller;
			#interrupt-cells = <0x2>;
		};

		gpio3@ff7a0000 {
			compatible = "rockchip,gpio-bank";
			reg = <0xff7a0000 0x100>;
			interrupts = <0x0 0x54 0x4>;
			clocks = <0x7 0x143>;
			gpio-controller;
			#gpio-cells = <0x2>;
			interrupt-controller;
			#interrupt-cells = <0x2>;
		};

		gpio4@ff7b0000 {
			compatible = "rockchip,gpio-bank";
			reg = <0xff7b0000 0x100>;
			interrupts = <0x0 0x55 0x4>;
			clocks = <0x7 0x144>;
			gpio-controller;
			#gpio-cells = <0x2>;
			interrupt-controller;
			#interrupt-cells = <0x2>;
			linux,phandle = <0x33>;
			phandle = <0x33>;
		};

		gpio5@ff7c0000 {
			compatible = "rockchip,gpio-bank";
			reg = <0xff7c0000 0x100>;
			interrupts = <0x0 0x56 0x4>;
			clocks = <0x7 0x145>;
			gpio-controller;
			#gpio-cells = <0x2>;
			interrupt-controller;
			#interrupt-cells = <0x2>;
		};

		gpio6@ff7d0000 {
			compatible = "rockchip,gpio-bank";
			reg = <0xff7d0000 0x100>;
			interrupts = <0x0 0x57 0x4>;
			clocks = <0x7 0x146>;
			gpio-controller;
			#gpio-cells = <0x2>;
			interrupt-controller;
			#interrupt-cells = <0x2>;
		};

		gpio7@ff7e0000 {
			compatible = "rockchip,gpio-bank";
			reg = <0xff7e0000 0x100>;
			interrupts = <0x0 0x58 0x4>;
			clocks = <0x7 0x147>;
			gpio-controller;
			#gpio-cells = <0x2>;
			interrupt-controller;
			#interrupt-cells = <0x2>;
			linux,phandle = <0x68>;
			phandle = <0x68>;
		};

		gpio8@ff7f0000 {
			compatible = "rockchip,gpio-bank";
			reg = <0xff7f0000 0x100>;
			interrupts = <0x0 0x59 0x4>;
			clocks = <0x7 0x148>;
			gpio-controller;
			#gpio-cells = <0x2>;
			interrupt-controller;
			#interrupt-cells = <0x2>;
		};

		hdmi {

			hdmi-ddc {
				rockchip,pins = <0x7 0x13 0x2 0x5f 0x7 0x14 0x2 0x5f>;
			};
		};

		pcfg-pull-up {
			bias-pull-up;
			linux,phandle = <0x60>;
			phandle = <0x60>;
		};

		pcfg-pull-down {
			bias-pull-down;
			linux,phandle = <0x61>;
			phandle = <0x61>;
		};

		pcfg-pull-none {
			bias-disable;
			linux,phandle = <0x5f>;
			phandle = <0x5f>;
		};

		pcfg-pull-none-12ma {
			bias-disable;
			drive-strength = <0xc>;
			linux,phandle = <0x64>;
			phandle = <0x64>;
		};

		sleep {

			global-pwroff {
				rockchip,pins = <0x0 0x0 0x1 0x5f>;
			};

			ddrio-pwroff {
				rockchip,pins = <0x0 0x1 0x1 0x5f>;
			};

			ddr0-retention {
				rockchip,pins = <0x0 0x2 0x1 0x60>;
			};

			ddr1-retention {
				rockchip,pins = <0x0 0x3 0x1 0x60>;
			};
		};

		edp {

			edp-hpd {
				rockchip,pins = <0x7 0xb 0x2 0x61>;
			};
		};

		i2c0 {

			i2c0-xfer {
				rockchip,pins = <0x0 0xf 0x1 0x5f 0x0 0x10 0x1 0x5f>;
				linux,phandle = <0x39>;
				phandle = <0x39>;
			};
		};

		i2c1 {

			i2c1-xfer {
				rockchip,pins = <0x8 0x4 0x1 0x5f 0x8 0x5 0x1 0x5f>;
				linux,phandle = <0x24>;
				phandle = <0x24>;
			};
		};

		i2c2 {

			i2c2-xfer {
				rockchip,pins = <0x6 0x9 0x1 0x5f 0x6 0xa 0x1 0x5f>;
				linux,phandle = <0x3f>;
				phandle = <0x3f>;
			};
		};

		i2c3 {

			i2c3-xfer {
				rockchip,pins = <0x2 0x10 0x1 0x5f 0x2 0x11 0x1 0x5f>;
				linux,phandle = <0x25>;
				phandle = <0x25>;
			};
		};

		i2c4 {

			i2c4-xfer {
				rockchip,pins = <0x7 0x11 0x1 0x5f 0x7 0x12 0x1 0x5f>;
				linux,phandle = <0x26>;
				phandle = <0x26>;
			};
		};

		i2c5 {

			i2c5-xfer {
				rockchip,pins = <0x7 0x13 0x1 0x5f 0x7 0x14 0x1 0x5f>;
				linux,phandle = <0x27>;
				phandle = <0x27>;
			};
		};

		i2s0 {

			i2s0-bus {
				rockchip,pins = <0x6 0x0 0x1 0x5f 0x6 0x1 0x1 0x5f 0x6 0x2 0x1 0x5f 0x6 0x3 0x1 0x5f 0x6 0x4 0x1 0x5f 0x6 0x8 0x1 0x5f>;
				linux,phandle = <0x46>;
				phandle = <0x46>;
			};
		};

		lcdc0 {

			lcdc0-ctl {
				rockchip,pins = <0x1 0x18 0x1 0x5f 0x1 0x19 0x1 0x5f 0x1 0x1a 0x1 0x5f 0x1 0x1b 0x1 0x5f>;
				linux,phandle = <0x57>;
				phandle = <0x57>;
			};
		};

		sdmmc {

			sdmmc-clk {
				rockchip,pins = <0x6 0x14 0x1 0x62>;
				linux,phandle = <0xd>;
				phandle = <0xd>;
			};

			sdmmc-cmd {
				rockchip,pins = <0x6 0x15 0x1 0x63>;
				linux,phandle = <0xe>;
				phandle = <0xe>;
			};

			sdmcc-cd {
				rockchip,pins = <0x6 0x16 0x1 0x60>;
				linux,phandle = <0xf>;
				phandle = <0xf>;
			};

			sdmmc-bus1 {
				rockchip,pins = <0x6 0x10 0x1 0x60>;
			};

			sdmmc-bus4 {
				rockchip,pins = <0x6 0x10 0x1 0x63 0x6 0x11 0x1 0x63 0x6 0x12 0x1 0x63 0x6 0x13 0x1 0x63>;
				linux,phandle = <0x10>;
				phandle = <0x10>;
			};

			sdmmc-pwr {
				rockchip,pins = <0x7 0xb 0x0 0x5f>;
				linux,phandle = <0x6b>;
				phandle = <0x6b>;
			};
		};

		sdio0 {

			sdio0-bus1 {
				rockchip,pins = <0x4 0x14 0x1 0x60>;
			};

			sdio0-bus4 {
				rockchip,pins = <0x4 0x14 0x1 0x60 0x4 0x15 0x1 0x60 0x4 0x16 0x1 0x60 0x4 0x17 0x1 0x60>;
			};

			sdio0-cmd {
				rockchip,pins = <0x4 0x18 0x1 0x60>;
			};

			sdio0-clk {
				rockchip,pins = <0x4 0x19 0x1 0x5f>;
			};

			sdio0-cd {
				rockchip,pins = <0x4 0x1a 0x1 0x60>;
			};

			sdio0-wp {
				rockchip,pins = <0x4 0x1b 0x1 0x60>;
			};

			sdio0-pwr {
				rockchip,pins = <0x4 0x1c 0x1 0x60>;
			};

			sdio0-bkpwr {
				rockchip,pins = <0x4 0x1d 0x1 0x60>;
			};

			sdio0-int {
				rockchip,pins = <0x4 0x1e 0x1 0x60>;
			};
		};

		sdio1 {

			sdio1-bus1 {
				rockchip,pins = <0x3 0x18 0x4 0x60>;
			};

			sdio1-bus4 {
				rockchip,pins = <0x3 0x18 0x4 0x60 0x3 0x19 0x4 0x60 0x3 0x1a 0x4 0x60 0x3 0x1b 0x4 0x60>;
			};

			sdio1-cd {
				rockchip,pins = <0x3 0x1c 0x4 0x60>;
			};

			sdio1-wp {
				rockchip,pins = <0x3 0x1d 0x4 0x60>;
			};

			sdio1-bkpwr {
				rockchip,pins = <0x3 0x1e 0x4 0x60>;
			};

			sdio1-int {
				rockchip,pins = <0x3 0x1f 0x4 0x60>;
			};

			sdio1-cmd {
				rockchip,pins = <0x4 0x6 0x4 0x60>;
			};

			sdio1-clk {
				rockchip,pins = <0x4 0x7 0x4 0x5f>;
			};

			sdio1-pwr {
				rockchip,pins = <0x4 0x9 0x4 0x60>;
			};
		};

		emmc {

			emmc-clk {
				rockchip,pins = <0x3 0x12 0x2 0x5f>;
				linux,phandle = <0x13>;
				phandle = <0x13>;
			};

			emmc-cmd {
				rockchip,pins = <0x3 0x10 0x2 0x60>;
				linux,phandle = <0x14>;
				phandle = <0x14>;
			};

			emmc-pwr {
				rockchip,pins = <0x3 0x9 0x2 0x60>;
				linux,phandle = <0x15>;
				phandle = <0x15>;
			};

			emmc-bus1 {
				rockchip,pins = <0x3 0x0 0x2 0x60>;
			};

			emmc-bus4 {
				rockchip,pins = <0x3 0x0 0x2 0x60 0x3 0x1 0x2 0x60 0x3 0x2 0x2 0x60 0x3 0x3 0x2 0x60>;
			};

			emmc-bus8 {
				rockchip,pins = <0x3 0x0 0x2 0x60 0x3 0x1 0x2 0x60 0x3 0x2 0x2 0x60 0x3 0x3 0x2 0x60 0x3 0x4 0x2 0x60 0x3 0x5 0x2 0x60 0x3 0x6 0x2 0x60 0x3 0x7 0x2 0x60>;
				linux,phandle = <0x16>;
				phandle = <0x16>;
			};
		};

		spi0 {

			spi0-clk {
				rockchip,pins = <0x5 0xc 0x1 0x60>;
				linux,phandle = <0x18>;
				phandle = <0x18>;
			};

			spi0-cs0 {
				rockchip,pins = <0x5 0xd 0x1 0x60>;
				linux,phandle = <0x1b>;
				phandle = <0x1b>;
			};

			spi0-tx {
				rockchip,pins = <0x5 0xe 0x1 0x60>;
				linux,phandle = <0x19>;
				phandle = <0x19>;
			};

			spi0-rx {
				rockchip,pins = <0x5 0xf 0x1 0x60>;
				linux,phandle = <0x1a>;
				phandle = <0x1a>;
			};

			spi0-cs1 {
				rockchip,pins = <0x5 0x10 0x1 0x60>;
			};
		};

		spi1 {

			spi1-clk {
				rockchip,pins = <0x7 0xc 0x2 0x60>;
				linux,phandle = <0x1c>;
				phandle = <0x1c>;
			};

			spi1-cs0 {
				rockchip,pins = <0x7 0xd 0x2 0x60>;
				linux,phandle = <0x1f>;
				phandle = <0x1f>;
			};

			spi1-rx {
				rockchip,pins = <0x7 0xe 0x2 0x60>;
				linux,phandle = <0x1e>;
				phandle = <0x1e>;
			};

			spi1-tx {
				rockchip,pins = <0x7 0xf 0x2 0x60>;
				linux,phandle = <0x1d>;
				phandle = <0x1d>;
			};
		};

		spi2 {

			spi2-cs1 {
				rockchip,pins = <0x8 0x3 0x1 0x60>;
			};

			spi2-clk {
				rockchip,pins = <0x8 0x6 0x1 0x60>;
				linux,phandle = <0x20>;
				phandle = <0x20>;
			};

			spi2-cs0 {
				rockchip,pins = <0x8 0x7 0x1 0x60>;
				linux,phandle = <0x23>;
				phandle = <0x23>;
			};

			spi2-rx {
				rockchip,pins = <0x8 0x8 0x1 0x60>;
				linux,phandle = <0x22>;
				phandle = <0x22>;
			};

			spi2-tx {
				rockchip,pins = <0x8 0x9 0x1 0x60>;
				linux,phandle = <0x21>;
				phandle = <0x21>;
			};
		};

		uart0 {

			uart0-xfer {
				rockchip,pins = <0x4 0x10 0x1 0x60 0x4 0x11 0x1 0x5f>;
				linux,phandle = <0x28>;
				phandle = <0x28>;
			};

			uart0-cts {
				rockchip,pins = <0x4 0x12 0x1 0x60>;
			};

			uart0-rts {
				rockchip,pins = <0x4 0x13 0x1 0x5f>;
			};
		};

		uart1 {

			uart1-xfer {
				rockchip,pins = <0x5 0x8 0x1 0x60 0x5 0x9 0x1 0x5f>;
				linux,phandle = <0x29>;
				phandle = <0x29>;
			};

			uart1-cts {
				rockchip,pins = <0x5 0xa 0x1 0x60>;
			};

			uart1-rts {
				rockchip,pins = <0x5 0xb 0x1 0x5f>;
			};
		};

		uart2 {

			uart2-xfer {
				rockchip,pins = <0x7 0x16 0x1 0x60 0x7 0x17 0x1 0x5f>;
				linux,phandle = <0x2a>;
				phandle = <0x2a>;
			};
		};

		uart3 {

			uart3-xfer {
				rockchip,pins = <0x7 0x7 0x1 0x60 0x7 0x8 0x1 0x5f>;
				linux,phandle = <0x2b>;
				phandle = <0x2b>;
			};

			uart3-cts {
				rockchip,pins = <0x7 0x9 0x1 0x60>;
			};

			uart3-rts {
				rockchip,pins = <0x7 0xa 0x1 0x5f>;
			};
		};

		uart4 {

			uart4-xfer {
				rockchip,pins = <0x5 0xc 0x3 0x60 0x5 0xd 0x3 0x5f>;
				linux,phandle = <0x2c>;
				phandle = <0x2c>;
			};

			uart4-cts {
				rockchip,pins = <0x5 0xe 0x3 0x60>;
			};

			uart4-rts {
				rockchip,pins = <0x5 0xf 0x3 0x5f>;
			};
		};

		tsadc {

			otp-gpio {
				rockchip,pins = <0x0 0xa 0x0 0x5f>;
				linux,phandle = <0x30>;
				phandle = <0x30>;
			};

			otp-out {
				rockchip,pins = <0x0 0xa 0x1 0x5f>;
				linux,phandle = <0x31>;
				phandle = <0x31>;
			};
		};

		pwm0 {

			pwm0-pin {
				rockchip,pins = <0x7 0x0 0x1 0x5f>;
				linux,phandle = <0x40>;
				phandle = <0x40>;
			};
		};

		pwm1 {

			pwm1-pin {
				rockchip,pins = <0x7 0x1 0x1 0x5f>;
				linux,phandle = <0x41>;
				phandle = <0x41>;
			};
		};

		pwm2 {

			pwm2-pin {
				rockchip,pins = <0x7 0x16 0x3 0x5f>;
				linux,phandle = <0x42>;
				phandle = <0x42>;
			};
		};

		pwm3 {

			pwm3-pin {
				rockchip,pins = <0x7 0x17 0x3 0x5f>;
				linux,phandle = <0x43>;
				phandle = <0x43>;
			};
		};

		gmac {

			rgmii-pins {
				rockchip,pins = <0x3 0x1e 0x3 0x5f 0x3 0x1f 0x3 0x5f 0x3 0x1a 0x3 0x5f 0x3 0x1b 0x3 0x5f 0x3 0x1c 0x3 0x64 0x3 0x1d 0x3 0x64 0x3 0x18 0x3 0x64 0x3 0x19 0x3 0x64 0x4 0x0 0x3 0x5f 0x4 0x5 0x3 0x5f 0x4 0x6 0x3 0x5f 0x4 0x9 0x3 0x64 0x4 0x4 0x3 0x64 0x4 0x1 0x3 0x5f 0x4 0x3 0x3 0x5f>;
				linux,phandle = <0x35>;
				phandle = <0x35>;
			};

			rmii-pins {
				rockchip,pins = <0x3 0x1e 0x3 0x5f 0x3 0x1f 0x3 0x5f 0x3 0x1c 0x3 0x5f 0x3 0x1d 0x3 0x5f 0x4 0x0 0x3 0x5f 0x4 0x5 0x3 0x5f 0x4 0x4 0x3 0x5f 0x4 0x1 0x3 0x5f 0x4 0x2 0x3 0x5f 0x4 0x3 0x3 0x5f>;
			};
		};

		spdif {

			spdif-tx {
				rockchip,pins = <0x6 0xb 0x1 0x5f>;
				linux,phandle = <0x45>;
				phandle = <0x45>;
			};
		};

		pcfg-pull-none-drv-8ma {
			drive-strength = <0x8>;
			linux,phandle = <0x62>;
			phandle = <0x62>;
		};

		pcfg-pull-up-drv-8ma {
			bias-pull-up;
			drive-strength = <0x8>;
			linux,phandle = <0x63>;
			phandle = <0x63>;
		};

		buttons {

			gkey {
				rockchip,pins = <0x7 0x9 0x0 0x60>;
				linux,phandle = <0x67>;
				phandle = <0x67>;
			};
		};

		pmic {

			pmic-int {
				rockchip,pins = <0x0 0x4 0x0 0x60>;
				linux,phandle = <0x3c>;
				phandle = <0x3c>;
			};
		};

		usb {

			host-vbus-drv {
				rockchip,pins = <0x0 0xe 0x0 0x5f>;
				linux,phandle = <0x69>;
				phandle = <0x69>;
			};

			pwr-3g {
				rockchip,pins = <0x7 0x8 0x0 0x5f>;
			};
		};

		eth_phy {

			eth-phy-pwr {
				rockchip,pins = <0x0 0x6 0x0 0x5f>;
				linux,phandle = <0x6a>;
				phandle = <0x6a>;
			};
		};
	};

	sound {
		compatible = "simple-audio-card";
		simple-audio-card,format = "i2s";
		simple-audio-card,name = "DW-HDMI";
		simple-audio-card,mclk-fs = <0x200>;

		simple-audio-card,dai-link@0 {
			format = "i2s";

			cpu {
				sound-dai = <0x65>;
			};

			codec {
				sound-dai = <0x66>;
			};
		};
	};

	external-gmac-clock {
		compatible = "fixed-clock";
		clock-frequency = <0x7735940>;
		clock-output-names = "ext_gmac";
		#clock-cells = <0x0>;
		linux,phandle = <0x34>;
		phandle = <0x34>;
	};

	gpio-keys {
		compatible = "gpio-keys";
		#address-cells = <0x1>;
		#size-cells = <0x0>;
		autorepeat;
		pinctrl-names = "default";
		pinctrl-0 = <0x67>;

		button@0 {
			gpios = <0x68 0x9 0x1>;
			linux,code = <0x74>;
			label = "GPIO Key";
			linux,input-type = <0x1>;
			debounce-interval = <0x64>;
		};
	};

	vcc-host-regulator {
		compatible = "regulator-fixed";
		enable-active-high;
		gpio = <0x3b 0xe 0x0>;
		pinctrl-names = "default";
		pinctrl-0 = <0x69>;
		regulator-name = "vcc_host";
		regulator-always-on;
		regulator-boot-on;
	};

	vcc-phy-regulator {
		compatible = "regulator-fixed";
		enable-active-high;
		gpio = <0x3b 0x6 0x0>;
		pinctrl-names = "default";
		pinctrl-0 = <0x6a>;
		regulator-name = "vcc_phy";
		regulator-min-microvolt = <0x325aa0>;
		regulator-max-microvolt = <0x325aa0>;
		regulator-always-on;
		regulator-boot-on;
		linux,phandle = <0x32>;
		phandle = <0x32>;
	};

	vsys-regulator {
		compatible = "regulator-fixed";
		regulator-name = "vcc_sys";
		regulator-min-microvolt = <0x4c4b40>;
		regulator-max-microvolt = <0x4c4b40>;
		regulator-always-on;
		regulator-boot-on;
		linux,phandle = <0x3a>;
		phandle = <0x3a>;
	};

	sdmmc-regulator {
		compatible = "regulator-fixed";
		gpio = <0x68 0xb 0x1>;
		pinctrl-names = "default";
		pinctrl-0 = <0x6b>;
		regulator-name = "vcc_sd";
		regulator-min-microvolt = <0x325aa0>;
		regulator-max-microvolt = <0x325aa0>;
		startup-delay-us = <0x186a0>;
		vin-supply = <0x3d>;
		linux,phandle = <0x11>;
		phandle = <0x11>;
	};

	io-domains {
		compatible = "rockchip,rk3288-io-voltage-domain";
		rockchip,grf = <0x9>;
		sdcard-supply = <0x12>;
	};

	board-leds {
		compatible = "gpio-leds";
		status = "okay";

		work {
			label = "System";
			linux,default-trigger = "timer";
			default-state = "on";
			gpios = <0x68 0x2 0x0>;
		};

		fan {
			label = "Fan";
			linux,default-trigger = "heartbeat";
			default-state = "on";
			gpios = <0x3f 0x12 0x0>;
		};
	};
};
